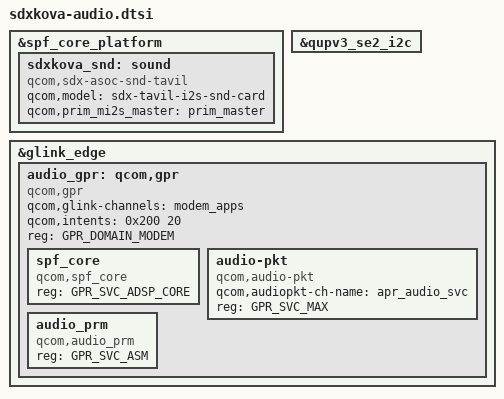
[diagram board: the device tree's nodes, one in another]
// SPDX-License-Identifier: BSD-3-Clause
/*
 * Copyright (c) 2024 Qualcomm Innovation Center, Inc. All rights reserved.
 */

#include "sdx-audio-lpass.dtsi"
#include "sdxkova-audio-overlay.dtsi"
#include "bindings/qcom,audio-ext-clk.h"
#include "bindings/qcom,gpr.h"

&spf_core_platform {
	sdxkova_snd: sound {
		compatible = "qcom,sdx-asoc-snd-tavil";
		qcom,model = "sdx-tavil-i2s-snd-card";
		qcom,prim_mi2s_master = <&prim_master>;
	};
};

&qupv3_se2_i2c {
	status = "okay";
};

&glink_edge {
	audio_gpr: qcom,gpr {
		compatible = "qcom,gpr";
		qcom,glink-channels = "modem_apps";
		qcom,intents = <0x200 20>;
		reg = <GPR_DOMAIN_MODEM>;

		spf_core {
			compatible = "qcom,spf_core";
			reg = <GPR_SVC_ADSP_CORE>;
		};

		audio-pkt {
			compatible = "qcom,audio-pkt";
			qcom,audiopkt-ch-name = "apr_audio_svc";
			reg = <GPR_SVC_MAX>;
		};

		audio_prm {
			compatible = "qcom,audio_prm";
			reg = <GPR_SVC_ASM>;
		};
	};
};

